# ADSP-2183x_LPC register map
Vendor: Analog Devices; Series: ADSP-2183x_LPC; File version: 3.0.3.517
CPU: 
Registers are 32-bit, read-write, reset 0x0 unless marked. A register's access mark holds for its fields unless they carry their own. Offsets are from the block's base; [hi:lo] are bit positions.

## CGU0 — Clock Generation Unit
Base 0x3108D000
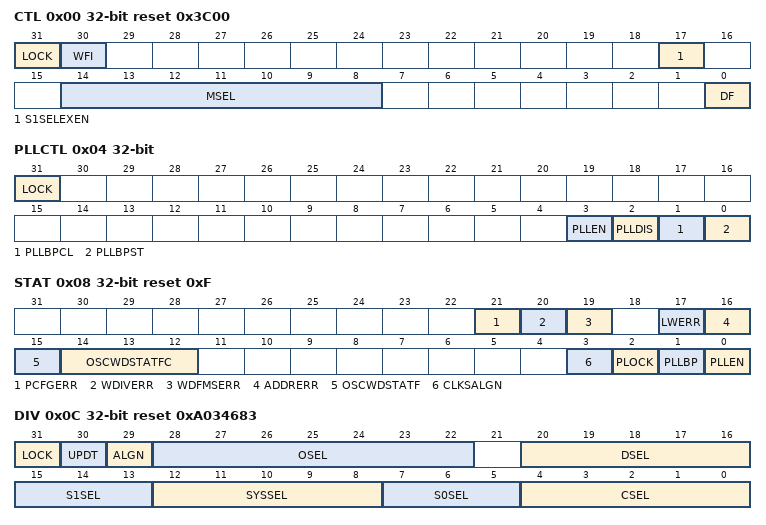
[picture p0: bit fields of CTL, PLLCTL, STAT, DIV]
0x00 CTL reset 0x3C00 — Control Register
  [31] LOCK
  [30] WFI — Wait For Idle
  [17] S1SELEXEN — SCLK1 Extension Divider Enable
  [14:8] MSEL — Multiplier Select
  [0] DF — Divide Frequency
0x04 PLLCTL — PLL Control Register
  [31] LOCK
  [3] PLLEN — PLL Enable
  [2] PLLDIS — PLL Disable
  [1] PLLBPCL — PLL Bypass Clear
  [0] PLLBPST — PLL Bypass Set
0x08 STAT reset 0xF — Status Register
  [21] PCFGERR — PLL Configuration Error
  [20] WDIVERR — Write to DIV Error
  [19] WDFMSERR — Write to MSEL Error
  [17] LWERR — Lock Write Error
  [16] ADDRERR — Address Error
  [15] OSCWDSTATF ro — Oscillator Watchdog Status Fault
  [14:12] OSCWDSTATFC ro — Oscillator Watchdog Status Fault Code
  [3] CLKSALGN ro — Clock Alignment
  [2] PLOCK ro — PLL Lock
  [1] PLLBP ro — PLL Bypass
  [0] PLLEN ro — PLL Enable
0x0C DIV reset 0xA034683 — Clocks Divisor Register
  [31] LOCK
  [30] UPDT — Update Clock Divisors
  [29] ALGN — Align
  [28:22] OSEL — OCLK Divisor
  [20:16] DSEL — XCLK Divisor
  [15:13] S1SEL — SCLK 1 Divisor
  [12:8] SYSSEL — SYSCLK Divisor
  [7:5] S0SEL — SCLK 0 Divisor
  [4:0] CSEL — CCLK Divisor
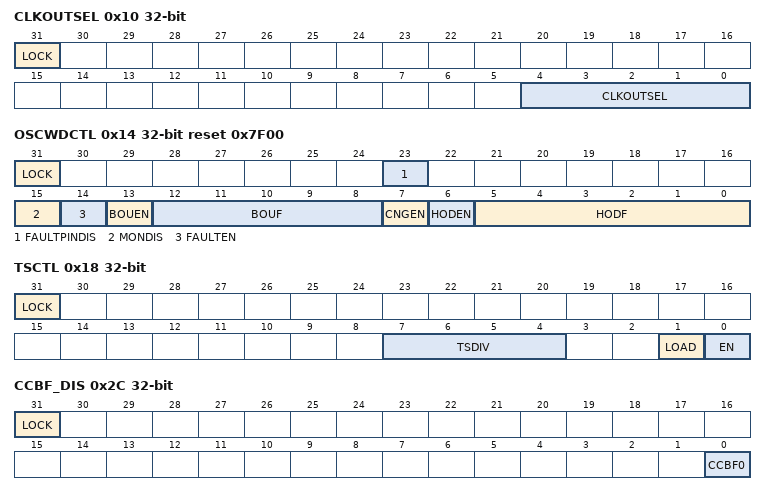
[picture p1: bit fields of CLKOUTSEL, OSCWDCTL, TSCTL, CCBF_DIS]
0x10 CLKOUTSEL — CLKOUT Select Register
  [31] LOCK
  [4:0] CLKOUTSEL — CLKOUT Select
    0=CLKIN0; 2=SYSCLK0_0 (PLLTOP0.SYSCLKO); 3=CCLK0_0 (PLLTOP0.CCLK0); 4=CLKO3 (CDU.CLKO3 for DDR); 7=CLKO8 (CDU.CLKO8 for LP); 8=SYSCLK0_1 (PLLTOP1.SYSCLKO); 9=OCLK0_1 (PLLTOP1.OCLK); 10=OCLK0_0 (PLLTOP0.OCLK); 14=SCLK1_0 (PLLTOP0.SCLK1); 16=SCLK0_0 (PLLTOP0.SCLK0); 19=CLKO2 (CDU.CLKO2 for ARM Core); 20=GND
0x14 OSCWDCTL reset 0x7F00 — Oscillator Watchdog Register
  [31] LOCK range 0x00000000..0x00000001
  [23] FAULTPINDIS range 0x00000000..0x00000001 — Fault Pin disabled
  [15] MONDIS range 0x00000000..0x00000001 — Oscillator Watchdog Monitor functions disabled
  [14] FAULTEN range 0x00000000..0x00000001 — Fault enabled
  [13] BOUEN range 0x00000000..0x00000001 — Bad Oscillator Upper Frequency limit detection enabled
  [12:8] BOUF range 0x00000000..0x0000001F — Bad Oscillator Upper Frequency limit
  [7] CNGEN range 0x00000000..0x00000001 — Clock not Good enabled
  [6] HODEN range 0x00000000..0x00000001 — Harmonic Oscillation Detection enabled
  [5:0] HODF range 0x00000000..0x0000003F — Watchdog lower frequency limit
0x18 TSCTL — Time Stamp Control Register
  [31] LOCK
  [7:4] TSDIV — Counter's Clock Divider
  [1] LOAD — Load Counter
  [0] EN — Counter Enable
0x1C TSVALUE0 — Time Stamp Counter Initial 32 LSB Value Register
  [31:0] VALUE range 0x00000000..0xFFFFFFFF — Counter's 32 LSB Initial Value
0x20 TSVALUE1 — Time Stamp Counter Initial MSB Value Register
  [31:0] VALUE range 0x00000000..0xFFFFFFFF — Counter's Initial 32 MSB Value
0x24 TSCOUNT0 — Time Stamp Counter 32 LSB Register
  [31:0] VALUE ro — TSCOUNT0 Value
0x28 TSCOUNT1 — Time Stamp Counter 32 MSB Register
  [31:0] VALUE ro — Timestamp Counter 32 MSB
0x2C CCBF_DIS — Core Clock Buffer Disable Register
  [31] LOCK
  [0] CCBF0 — Core Clock Buffer 0
0x30 CCBF_STAT — Core Clock Buffer Status Register
  [0] CCBF0 ro — Core Clock Buffer 0
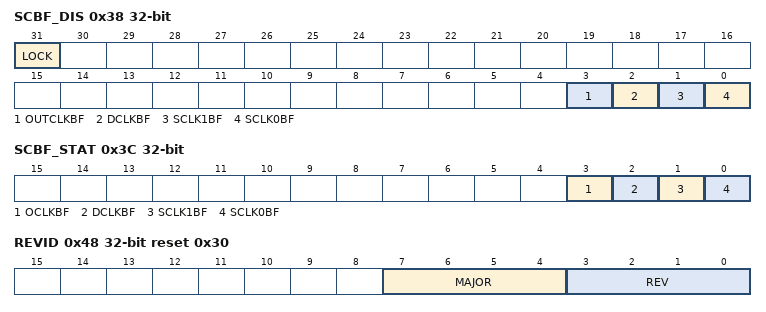
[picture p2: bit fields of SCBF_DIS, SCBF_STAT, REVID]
0x38 SCBF_DIS — System Clock Buffer Disable Register
  [31] LOCK
  [3] OUTCLKBF — OCLK Buffer
  [2] DCLKBF — XCLK Buffer
  [1] SCLK1BF — SCLK1 Buffer
  [0] SCLK0BF — SCLK0 Buffer
0x3C SCBF_STAT — System Clock Buffer Status Register
  [3] OCLKBF ro — OCLK Buffer
  [2] DCLKBF ro — XCLK1 Buffer
  [1] SCLK1BF ro — SCLK1 Buffer
  [0] SCLK0BF ro — SCLK0 Buffer
0x40 DIVEX reset 0x200030 — DIV Register Extension
  [23:16] S1SELEX — SCLK 1 Extension Divisor
0x48 REVID reset 0x30 — Revision ID Register
  [7:4] MAJOR ro — Major Version
  [3:0] REV ro — Incremental Version ID

## CGU1 — Clock Generation Unit
Base 0x3108E000
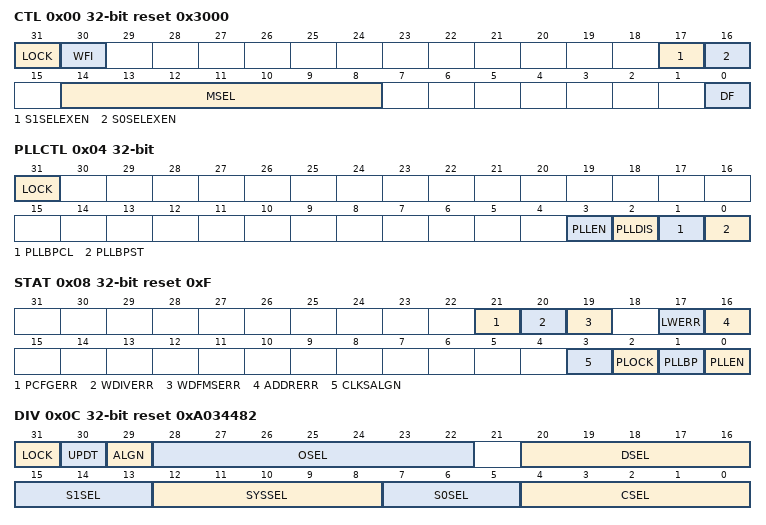
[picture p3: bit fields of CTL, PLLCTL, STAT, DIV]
0x00 CTL reset 0x3000 — Control Register
  [31] LOCK
  [30] WFI — Wait For Idle
  [17] S1SELEXEN — SCLK1 Extension Divider Enable
  [16] S0SELEXEN — SCLK0 Extension Divider Enable
  [14:8] MSEL — Multiplier Select
  [0] DF — Divide Frequency
0x04 PLLCTL — PLL Control Register
  [31] LOCK
  [3] PLLEN — PLL Enable
  [2] PLLDIS — PLL Disable
  [1] PLLBPCL — PLL Bypass Clear
  [0] PLLBPST — PLL Bypass Set
0x08 STAT reset 0xF — Status Register
  [21] PCFGERR — PLL Configuration Error
  [20] WDIVERR — Write to DIV Error
  [19] WDFMSERR — Write to MSEL Error
  [17] LWERR — Lock Write Error
  [16] ADDRERR — Address Error
  [3] CLKSALGN ro — Clock Alignment
  [2] PLOCK ro — PLL Lock
  [1] PLLBP ro — PLL Bypass
  [0] PLLEN ro — PLL Enable
0x0C DIV reset 0xA034482 — Clocks Divisor Register
  [31] LOCK
  [30] UPDT — Update Clock Divisors
  [29] ALGN — Align
  [28:22] OSEL — OCLK Divisor
  [20:16] DSEL — XCLK Divisor
  [15:13] S1SEL — SCLK 1 Divisor
  [12:8] SYSSEL — SYSCLK Divisor
  [7:5] S0SEL — SCLK 0 Divisor
  [4:0] CSEL — CCLK Divisor
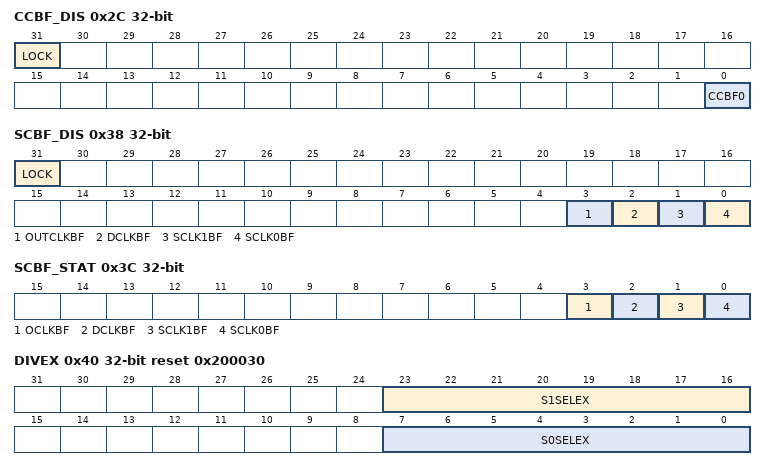
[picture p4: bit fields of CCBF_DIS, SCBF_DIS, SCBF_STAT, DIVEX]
0x2C CCBF_DIS — Core Clock Buffer Disable Register
  [31] LOCK
  [0] CCBF0 — Core Clock Buffer 0
0x30 CCBF_STAT — Core Clock Buffer Status Register
  [0] CCBF0 ro — Core Clock Buffer 0
0x38 SCBF_DIS — System Clock Buffer Disable Register
  [31] LOCK
  [3] OUTCLKBF — OCLK Buffer
  [2] DCLKBF — XCLK Buffer
  [1] SCLK1BF — SCLK1 Buffer
  [0] SCLK0BF — SCLK0 Buffer
0x3C SCBF_STAT — System Clock Buffer Status Register
  [3] OCLKBF ro — OCLK Buffer
  [2] DCLKBF ro — XCLK1 Buffer
  [1] SCLK1BF ro — SCLK1 Buffer
  [0] SCLK0BF ro — SCLK0 Buffer
0x40 DIVEX reset 0x200030 — DIV Register Extension
  [23:16] S1SELEX — SCLK 1 Extension Divisor
  [7:0] S0SELEX — SCLK 0 Extension Divisor
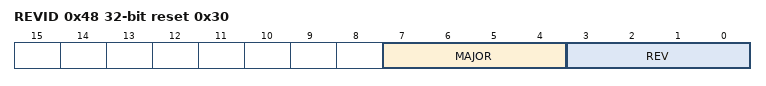
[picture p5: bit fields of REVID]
0x48 REVID reset 0x30 — Revision ID Register
  [7:4] MAJOR ro — Major Version
  [3:0] REV ro — Incremental Version ID

## Notices in the file
Copyright (c) 2018-2025 Analog Devices, Inc. All Rights Reserved.
This software is proprietary to Analog Devices, Inc. and its licensors.
